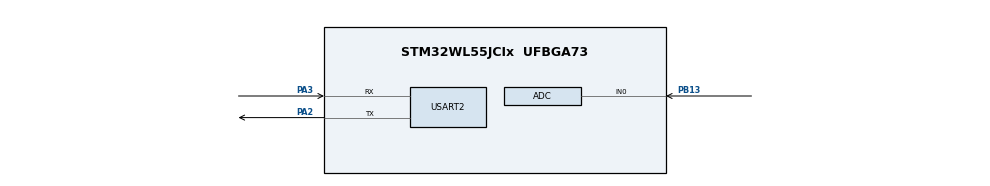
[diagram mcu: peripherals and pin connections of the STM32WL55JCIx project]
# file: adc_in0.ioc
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ADC.ClockPrescaler=ADC_CLOCK_ASYNC_DIV2
ADC.NbrOfConversion=1
ADC.SamplingTimeCommon1=ADC_SAMPLETIME_160CYCLES_5
ADC.SamplingTimeCommon2=ADC_SAMPLETIME_160CYCLES_5
ADC.SelectedChannel=ADC_CHANNEL_0|ADC_CHANNEL_VREFINT
Mcu.Family=STM32WL
Mcu.Name=STM32WL55JCIx
Mcu.Package=UFBGA73
NVIC.PriorityGroup=NVIC_PRIORITYGROUP_4
PA2.Mode=Asynchronous
PA2.Signal=USART2_TX
PA3.Mode=Asynchronous
PA3.Signal=USART2_RX
PB13.Mode=IN0
PB13.Signal=ADC_IN0
ProjectManager.HeapSize=0x200
ProjectManager.StackSize=0x400
ProjectManager.TargetToolchain=MDK-ARM V5.37
RCC.HSE_VALUE=8000000
RCC.HSI_VALUE=16000000
RCC.LSE_VALUE=32768
RCC.VCOOutputFreq_Value=32000000
USART2.VirtualMode-Asynchronous=VM_ASYNC
VP_ADC_Vref_Input.Mode=IN-Vrefint
board=custom

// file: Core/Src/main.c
/* USER CODE BEGIN Header */
/**
  ******************************************************************************
  * @file           : main.c
  * @brief          : Main program body
  ******************************************************************************
  * @attention
  *
  * Copyright (c) 2023 STMicroelectronics.
  * All rights reserved.
  *
  * This software is licensed under terms that can be found in the LICENSE file
  * in the root directory of this software component.
  * If no LICENSE file comes with this software, it is provided AS-IS.
  *
  ******************************************************************************
  */
/* USER CODE END Header */
#include "main.h"

/* USER CODE BEGIN Includes */
#include <stdio.h>
/* USER CODE END Includes */

ADC_HandleTypeDef hadc;

UART_HandleTypeDef huart2;

void SystemClock_Config(void);
static void MX_GPIO_Init(void);
static void MX_ADC_Init(void);
static void MX_USART2_UART_Init(void);

int main(void)
{
  /* USER CODE BEGIN 1 */
	char data[40];
	uint16_t ADCxConvertedValues;
  /* USER CODE END 1 */

  /* MCU Configuration--------------------------------------------------------*/

  /* Reset of all peripherals, Initializes the Flash interface and the Systick. */
  HAL_Init();

  /* Configure the system clock */
  SystemClock_Config();

  /* Initialize all configured peripherals */
  MX_GPIO_Init();
  MX_ADC_Init();
  MX_USART2_UART_Init();

  /* Infinite loop */
  while (1)
  {

    /* USER CODE BEGIN 3 */
		/* Start ADC */
		HAL_ADC_Start(&hadc);
		/* Star conversion for ADC */
		HAL_ADC_PollForConversion(&hadc, 100);
		/* Get converted ADC value */
		ADCxConvertedValues = HAL_ADC_GetValue(&hadc);
		/* Stop ADC */
		HAL_ADC_Stop (&hadc);

		/* Copy ADC converted value into the data buffer */
		sprintf(data, " ADC IN0 channel value=%d mV\r\n ", (uint16_t) ((ADCxConvertedValues / 4095.0) * 3300) );

		HAL_UART_Transmit(&huart2, (uint8_t*)data, sizeof(data),0xFFFF);
	  HAL_Delay(100);
  }
  /* USER CODE END 3 */
}

void SystemClock_Config(void)
{
  RCC_OscInitTypeDef RCC_OscInitStruct = {0};
  RCC_ClkInitTypeDef RCC_ClkInitStruct = {0};

  /** Configure the main internal regulator output voltage
  */
  __HAL_PWR_VOLTAGESCALING_CONFIG(PWR_REGULATOR_VOLTAGE_SCALE1);

  /** Initializes the CPU, AHB and APB buses clocks
  */
  RCC_OscInitStruct.OscillatorType = RCC_OSCILLATORTYPE_HSI|RCC_OSCILLATORTYPE_MSI;
  RCC_OscInitStruct.HSIState = RCC_HSI_ON;
  RCC_OscInitStruct.MSIState = RCC_MSI_ON;
  RCC_OscInitStruct.HSICalibrationValue = RCC_HSICALIBRATION_DEFAULT;
  RCC_OscInitStruct.MSICalibrationValue = RCC_MSICALIBRATION_DEFAULT;
  RCC_OscInitStruct.MSIClockRange = RCC_MSIRANGE_11;
  RCC_OscInitStruct.PLL.PLLState = RCC_PLL_NONE;
  if (HAL_RCC_OscConfig(&RCC_OscInitStruct) != HAL_OK)
  {
    Error_Handler();
  }

  /** Configure the SYSCLKSource, HCLK, PCLK1 and PCLK2 clocks dividers
  */
  RCC_ClkInitStruct.ClockType = RCC_CLOCKTYPE_HCLK3|RCC_CLOCKTYPE_HCLK
                              |RCC_CLOCKTYPE_SYSCLK|RCC_CLOCKTYPE_PCLK1
                              |RCC_CLOCKTYPE_PCLK2;
  RCC_ClkInitStruct.SYSCLKSource = RCC_SYSCLKSOURCE_MSI;
  RCC_ClkInitStruct.AHBCLKDivider = RCC_SYSCLK_DIV1;
  RCC_ClkInitStruct.APB1CLKDivider = RCC_HCLK_DIV1;
  RCC_ClkInitStruct.APB2CLKDivider = RCC_HCLK_DIV1;
  RCC_ClkInitStruct.AHBCLK3Divider = RCC_SYSCLK_DIV1;

  if (HAL_RCC_ClockConfig(&RCC_ClkInitStruct, FLASH_LATENCY_2) != HAL_OK)
  {
    Error_Handler();
  }
}

static void MX_ADC_Init(void)
{

  /** Configure the global features of the ADC (Clock, Resolution, Data Alignment and number of conversion)
  */
  hadc.Instance = ADC;
  hadc.Init.ClockPrescaler = ADC_CLOCK_ASYNC_DIV2;
  hadc.Init.Resolution = ADC_RESOLUTION_12B;
  hadc.Init.DataAlign = ADC_DATAALIGN_RIGHT;
  hadc.Init.ScanConvMode = ADC_SCAN_DISABLE;
  hadc.Init.EOCSelection = ADC_EOC_SINGLE_CONV;
  hadc.Init.LowPowerAutoWait = DISABLE;
  hadc.Init.LowPowerAutoPowerOff = DISABLE;
  hadc.Init.ContinuousConvMode = DISABLE;
  hadc.Init.NbrOfConversion = 1;
  hadc.Init.DiscontinuousConvMode = DISABLE;
  hadc.Init.ExternalTrigConv = ADC_SOFTWARE_START;
  hadc.Init.ExternalTrigConvEdge = ADC_EXTERNALTRIGCONVEDGE_NONE;
  hadc.Init.DMAContinuousRequests = DISABLE;
  hadc.Init.Overrun = ADC_OVR_DATA_PRESERVED;
  hadc.Init.SamplingTimeCommon1 = ADC_SAMPLETIME_160CYCLES_5;
  hadc.Init.SamplingTimeCommon2 = ADC_SAMPLETIME_160CYCLES_5;
  hadc.Init.OversamplingMode = DISABLE;
  hadc.Init.TriggerFrequencyMode = ADC_TRIGGER_FREQ_HIGH;
  if (HAL_ADC_Init(&hadc) != HAL_OK)
  {
    Error_Handler();
  }

}

static void MX_USART2_UART_Init(void)
{

  huart2.Instance = USART2;
  huart2.Init.BaudRate = 115200;
  huart2.Init.WordLength = UART_WORDLENGTH_8B;
  huart2.Init.StopBits = UART_STOPBITS_1;
  huart2.Init.Parity = UART_PARITY_NONE;
  huart2.Init.Mode = UART_MODE_TX_RX;
  huart2.Init.HwFlowCtl = UART_HWCONTROL_NONE;
  huart2.Init.OverSampling = UART_OVERSAMPLING_16;
  huart2.Init.OneBitSampling = UART_ONE_BIT_SAMPLE_DISABLE;
  huart2.Init.ClockPrescaler = UART_PRESCALER_DIV1;
  huart2.AdvancedInit.AdvFeatureInit = UART_ADVFEATURE_NO_INIT;
  if (HAL_UART_Init(&huart2) != HAL_OK)
  {
    Error_Handler();
  }
  if (HAL_UARTEx_SetTxFifoThreshold(&huart2, UART_TXFIFO_THRESHOLD_1_8) != HAL_OK)
  {
    Error_Handler();
  }
  if (HAL_UARTEx_SetRxFifoThreshold(&huart2, UART_RXFIFO_THRESHOLD_1_8) != HAL_OK)
  {
    Error_Handler();
  }
  if (HAL_UARTEx_DisableFifoMode(&huart2) != HAL_OK)
  {
    Error_Handler();
  }

}

static void MX_GPIO_Init(void)
{

  /* GPIO Ports Clock Enable */
  __HAL_RCC_GPIOB_CLK_ENABLE();
  __HAL_RCC_GPIOA_CLK_ENABLE();

}

void Error_Handler(void)
{
  __disable_irq();
  while (1)
  {
  }
}
